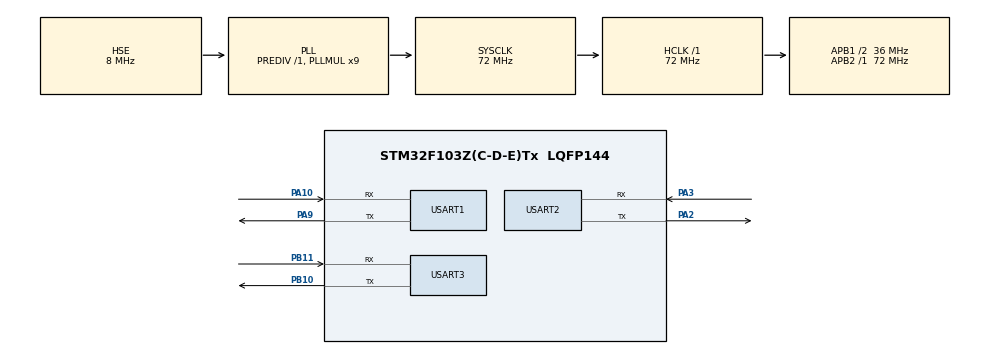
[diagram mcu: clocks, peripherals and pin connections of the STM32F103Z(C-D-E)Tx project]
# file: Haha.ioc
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Mcu.Family=STM32F1
Mcu.Name=STM32F103Z(C-D-E)Tx
Mcu.Package=LQFP144
NVIC.PriorityGroup=NVIC_PRIORITYGROUP_4
OSC_IN.Mode=HSE-External-Oscillator
OSC_IN.Signal=RCC_OSC_IN
OSC_OUT.Mode=HSE-External-Oscillator
OSC_OUT.Signal=RCC_OSC_OUT
PA10.Mode=Asynchronous
PA10.Signal=USART1_RX
PA13.Mode=Serial_Wire
PA13.Signal=SYS_JTMS-SWDIO
PA14.Mode=Serial_Wire
PA14.Signal=SYS_JTCK-SWCLK
PA2.Mode=Asynchronous
PA2.Signal=USART2_TX
PA3.Mode=Asynchronous
PA3.Signal=USART2_RX
PA9.Mode=Asynchronous
PA9.Signal=USART1_TX
PB10.Mode=Asynchronous
PB10.Signal=USART3_TX
PB11.Mode=Asynchronous
PB11.Signal=USART3_RX
PC14-OSC32_IN.Mode=LSE-External-Oscillator
PC14-OSC32_IN.Signal=RCC_OSC32_IN
PC15-OSC32_OUT.Mode=LSE-External-Oscillator
PC15-OSC32_OUT.Signal=RCC_OSC32_OUT
ProjectManager.HeapSize=0x200
ProjectManager.StackSize=0x400
ProjectManager.TargetToolchain=MDK-ARM V5.32
RCC.AHBFreq_Value=72000000
RCC.APB1CLKDivider=RCC_HCLK_DIV2
RCC.APB1Freq_Value=36000000
RCC.APB1TimFreq_Value=72000000
RCC.APB2Freq_Value=72000000
RCC.APB2TimFreq_Value=72000000
RCC.HCLKFreq_Value=72000000
RCC.PLLMUL=RCC_PLL_MUL9
RCC.PLLSourceVirtual=RCC_PLLSOURCE_HSE
RCC.SYSCLKFreq_VALUE=72000000
RCC.SYSCLKSource=RCC_SYSCLKSOURCE_PLLCLK
RCC.USBFreq_Value=72000000
USART1.VirtualMode=VM_ASYNC
USART2.VirtualMode=VM_ASYNC
USART3.VirtualMode=VM_ASYNC
board=custom

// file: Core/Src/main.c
/* USER CODE BEGIN Header */
/**
  ******************************************************************************
  * @file           : main.c
  * @brief          : Main program body
  ******************************************************************************
  * @attention
  *
  * Copyright (c) 2025 STMicroelectronics.
  * All rights reserved.
  *
  * This software is licensed under terms that can be found in the LICENSE file
  * in the root directory of this software component.
  * If no LICENSE file comes with this software, it is provided AS-IS.
  *
  ******************************************************************************
  */
/* USER CODE END Header */
#include "main.h"
#include "usart.h"
#include "gpio.h"

void SystemClock_Config(void);

int main(void)
{

  /* MCU Configuration--------------------------------------------------------*/

  /* Reset of all peripherals, Initializes the Flash interface and the Systick. */
  HAL_Init();

  /* Configure the system clock */
  SystemClock_Config();

  /* Initialize all configured peripherals */
  MX_GPIO_Init();
  MX_USART1_UART_Init();
  MX_USART2_UART_Init();
  MX_USART3_UART_Init();

  /* Infinite loop */
  /* USER CODE BEGIN WHILE */
  printf("USART2 OK!\r\n");
  uint8_t buff[50];
  buff[5]='t';
  buff[6]='p';
  while (1)
  {
    HAL_UART_Receive(&huart2, buff, 5, HAL_MAX_DELAY);
    //HAL_UART_Transmit(&huart1, buff, 7, HAL_MAX_DELAY);
    printf("USART1 Receive Data:%s",buff);
    memset(buff,0,5);
    /* USER CODE END WHILE */

  }
}

void SystemClock_Config(void)
{
  RCC_OscInitTypeDef RCC_OscInitStruct = {0};
  RCC_ClkInitTypeDef RCC_ClkInitStruct = {0};

  /** Initializes the RCC Oscillators according to the specified parameters
  * in the RCC_OscInitTypeDef structure.
  */
  RCC_OscInitStruct.OscillatorType = RCC_OSCILLATORTYPE_HSE;
  RCC_OscInitStruct.HSEState = RCC_HSE_ON;
  RCC_OscInitStruct.HSEPredivValue = RCC_HSE_PREDIV_DIV1;
  RCC_OscInitStruct.HSIState = RCC_HSI_ON;
  RCC_OscInitStruct.PLL.PLLState = RCC_PLL_ON;
  RCC_OscInitStruct.PLL.PLLSource = RCC_PLLSOURCE_HSE;
  RCC_OscInitStruct.PLL.PLLMUL = RCC_PLL_MUL9;
  if (HAL_RCC_OscConfig(&RCC_OscInitStruct) != HAL_OK)
  {
    Error_Handler();
  }

  /** Initializes the CPU, AHB and APB buses clocks
  */
  RCC_ClkInitStruct.ClockType = RCC_CLOCKTYPE_HCLK|RCC_CLOCKTYPE_SYSCLK
                              |RCC_CLOCKTYPE_PCLK1|RCC_CLOCKTYPE_PCLK2;
  RCC_ClkInitStruct.SYSCLKSource = RCC_SYSCLKSOURCE_PLLCLK;
  RCC_ClkInitStruct.AHBCLKDivider = RCC_SYSCLK_DIV1;
  RCC_ClkInitStruct.APB1CLKDivider = RCC_HCLK_DIV2;
  RCC_ClkInitStruct.APB2CLKDivider = RCC_HCLK_DIV1;

  if (HAL_RCC_ClockConfig(&RCC_ClkInitStruct, FLASH_LATENCY_2) != HAL_OK)
  {
    Error_Handler();
  }
}

void Error_Handler(void)
{
  __disable_irq();
  while (1)
  {
  }
}
